AUTOSAR XML (schema 4-2-2)
package /ComponentTypes
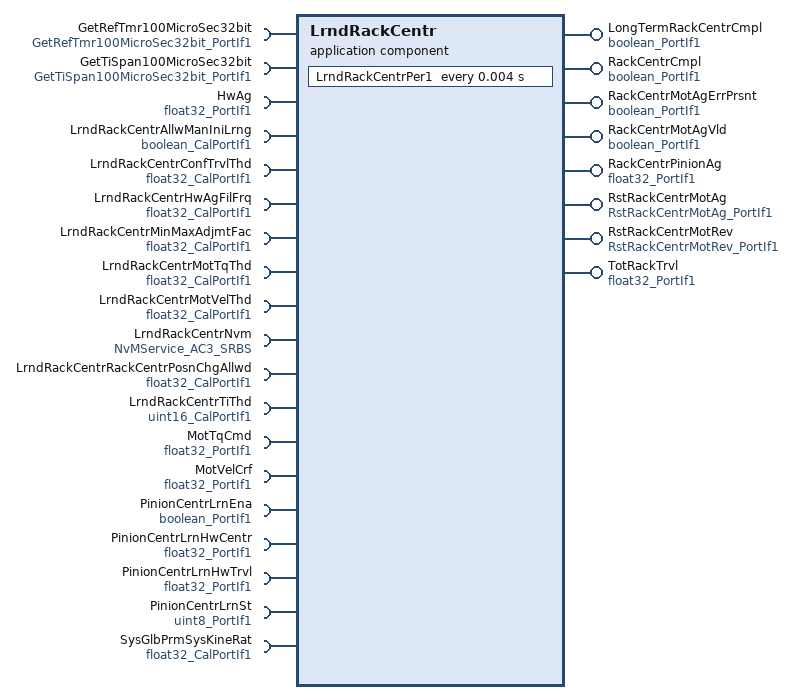
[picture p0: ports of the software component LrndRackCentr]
  application sw component type LrndRackCentr
    8 x provide port:
      LongTermRackCentrCmpl: nonqueued-sender-com-spec{data-element=Logl, init-value=0}, provided-interface=boolean_PortIf1
      RackCentrCmpl: nonqueued-sender-com-spec{data-element=Logl, init-value=0}, provided-interface=boolean_PortIf1
      RackCentrMotAgErrPrsnt: nonqueued-sender-com-spec{data-element=Logl, init-value=0}, provided-interface=boolean_PortIf1
      RackCentrMotAgVld: nonqueued-sender-com-spec{data-element=Logl, init-value=0}, provided-interface=boolean_PortIf1
      RackCentrPinionAg: nonqueued-sender-com-spec{data-element=Val, init-value=0}, provided-interface=float32_PortIf1
      RstRackCentrMotAg: server-com-spec{operation=Oper, queue-length=1}, provided-interface=RstRackCentrMotAg_PortIf1
      RstRackCentrMotRev: server-com-spec{operation=Oper, queue-length=1}, provided-interface=RstRackCentrMotRev_PortIf1
      TotRackTrvl: nonqueued-sender-com-spec{data-element=Val, init-value=0}, provided-interface=float32_PortIf1
    19 x require port:
      GetRefTmr100MicroSec32bit: client-com-spec=Oper, required-interface=GetRefTmr100MicroSec32bit_PortIf1
      GetTiSpan100MicroSec32bit: client-com-spec=Oper, required-interface=GetTiSpan100MicroSec32bit_PortIf1
      HwAg: nonqueued-receiver-com-spec{data-element=Val, filter=data-filter-type=ALWAYS, init-value=0}, required-interface=float32_PortIf1
      LrndRackCentrAllwManIniLrng: parameter-require-com-spec{init-value=1, parameter=Logl}, required-interface=boolean_CalPortIf1
      LrndRackCentrConfTrvlThd: parameter-require-com-spec{init-value=800, parameter=Val}, required-interface=float32_CalPortIf1
      LrndRackCentrHwAgFilFrq: parameter-require-com-spec{init-value=1, parameter=Val}, required-interface=float32_CalPortIf1
      LrndRackCentrMinMaxAdjmtFac: parameter-require-com-spec{init-value=0.25, parameter=Val}, required-interface=float32_CalPortIf1
      LrndRackCentrMotTqThd: parameter-require-com-spec{init-value=2.8, parameter=Val}, required-interface=float32_CalPortIf1
      LrndRackCentrMotVelThd: parameter-require-com-spec{init-value=25, parameter=Val}, required-interface=float32_CalPortIf1
      LrndRackCentrNvm: required-com-specs=[EraseBlock, GetErrorStatus, InvalidateNvBlock, ReadBlock, SetRamBlockStatus, WriteBlock], required-interface=NvMService_AC3_SRBS
      LrndRackCentrRackCentrPosnChgAllwd: parameter-require-com-spec{init-value=3, parameter=Val}, required-interface=float32_CalPortIf1
      LrndRackCentrTiThd: parameter-require-com-spec{init-value=200, parameter=Val}, required-interface=uint16_CalPortIf1
      MotTqCmd: nonqueued-receiver-com-spec{data-element=Val, filter=data-filter-type=ALWAYS, init-value=0}, required-interface=float32_PortIf1
      MotVelCrf: nonqueued-receiver-com-spec{data-element=Val, filter=data-filter-type=ALWAYS, init-value=0}, required-interface=float32_PortIf1
      PinionCentrLrnEna: nonqueued-receiver-com-spec{data-element=Logl, filter=data-filter-type=ALWAYS, init-value=0}, required-interface=boolean_PortIf1
      PinionCentrLrnHwCentr: nonqueued-receiver-com-spec{data-element=Val, filter=data-filter-type=ALWAYS, init-value=0}, required-interface=float32_PortIf1
      PinionCentrLrnHwTrvl: nonqueued-receiver-com-spec{data-element=Val, filter=data-filter-type=ALWAYS, init-value=0}, required-interface=float32_PortIf1
      PinionCentrLrnSt: nonqueued-receiver-com-spec{data-element=Val, filter=data-filter-type=ALWAYS, init-value=0}, required-interface=uint8_PortIf1
      SysGlbPrmSysKineRat: parameter-require-com-spec{init-value=22, parameter=Val}, required-interface=float32_CalPortIf1
    behavior LrndRackCentr_InternalBehavior: port-api-option{enable-take-address=false, error-handling=NO-TRANSFORMER-ERROR-HANDLING, indirect-api=false, port=LrndRackCentrNvm}
      ar-typed-per-instance-memorys:
        9 x data, all with sw-calibration-access=READ-ONLY:
          HwAgFil: type=FilLpRec1
          LrndRackCentr: type=LrndRackCentrNvmRec1
          ManLrndRackCentrNegEot: type=float32
          ManLrndRackCentrNegEotVld: type=boolean
          ManLrndRackCentrPosEot: type=float32
          ManLrndRackCentrPosEotVld: type=boolean
          RackCentrMaxTmr: type=uint32
          RackCentrMinTmr: type=uint32
          RackCentrPinionAgPrev: type=float32
      init event LrndRackCentr_InitEvent: start-on-event=LrndRackCentrInit1
      timing event TMT_LrndRackCentrPer1: start-on-event=LrndRackCentrPer1, period=0.004
      operation invoked event OIT_RstRackCentrMotAg_Oper_RstRackCentrMotAg_Oper: start-on-event=RstRackCentrMotAg_Oper, operation=RstRackCentrMotAg.Oper
      operation invoked event OIT_RstRackCentrMotRev_Oper_RstRackCentrMotRev_Oper: start-on-event=RstRackCentrMotRev_Oper, operation=RstRackCentrMotRev.Oper
      4 x runnable:
        LrndRackCentrInit1
          data-receive-point-by-arguments:
            access REC_HwAg_Val: accessed-variable=HwAg.Val
          data-send-points:
            5 x access:
              SEND_LongTermRackCentrCmpl_Logl: accessed-variable=LongTermRackCentrCmpl.Logl
              SEND_RackCentrCmpl_Logl: accessed-variable=RackCentrCmpl.Logl
              SEND_RackCentrMotAgErrPrsnt_Logl: accessed-variable=RackCentrMotAgErrPrsnt.Logl
              SEND_RackCentrMotAgVld_Logl: accessed-variable=RackCentrMotAgVld.Logl
              SEND_RackCentrPinionAg_Val: accessed-variable=RackCentrPinionAg.Val
          sync call SC_LrndRackCentrNvm_GetErrorStatus: operation=LrndRackCentrNvm.GetErrorStatus, timeout=0
        LrndRackCentrPer1
          data-receive-point-by-arguments:
            7 x access:
              REC_HwAg_Val: accessed-variable=HwAg.Val
              REC_MotTqCmd_Val: accessed-variable=MotTqCmd.Val
              REC_MotVelCrf_Val: accessed-variable=MotVelCrf.Val
              REC_PinionCentrLrnEna_Logl: accessed-variable=PinionCentrLrnEna.Logl
              REC_PinionCentrLrnHwCentr_Val: accessed-variable=PinionCentrLrnHwCentr.Val
              REC_PinionCentrLrnHwTrvl_Val: accessed-variable=PinionCentrLrnHwTrvl.Val
              REC_PinionCentrLrnSt_Val: accessed-variable=PinionCentrLrnSt.Val
          data-send-points:
            5 x access:
              SEND_LongTermRackCentrCmpl_Logl: accessed-variable=LongTermRackCentrCmpl.Logl
              SEND_RackCentrCmpl_Logl: accessed-variable=RackCentrCmpl.Logl
              SEND_RackCentrMotAgVld_Logl: accessed-variable=RackCentrMotAgVld.Logl
              SEND_RackCentrPinionAg_Val: accessed-variable=RackCentrPinionAg.Val
              SEND_TotRackTrvl_Val: accessed-variable=TotRackTrvl.Val
          sync call SC_GetRefTmr100MicroSec32bit_Oper: operation=GetRefTmr100MicroSec32bit.Oper, timeout=0
          sync call SC_GetTiSpan100MicroSec32bit_Oper: operation=GetTiSpan100MicroSec32bit.Oper, timeout=0
          sync call SC_LrndRackCentrNvm_SetRamBlockStatus: operation=LrndRackCentrNvm.SetRamBlockStatus, timeout=0
        RstRackCentrMotAg_Oper: can-be-invoked-concurrently=true
          data-send-points:
            access SEND_RackCentrMotAgVld_Logl: accessed-variable=RackCentrMotAgVld.Logl
          sync call SC_LrndRackCentrNvm_SetRamBlockStatus: operation=LrndRackCentrNvm.SetRamBlockStatus, timeout=0
        RstRackCentrMotRev_Oper: can-be-invoked-concurrently=true
          data-receive-point-by-arguments:
            access REC_HwAg_Val: accessed-variable=HwAg.Val
          data-send-points:
            access SEND_LongTermRackCentrCmpl_Logl: accessed-variable=LongTermRackCentrCmpl.Logl
            access SEND_RackCentrCmpl_Logl: accessed-variable=RackCentrCmpl.Logl
            access SEND_RackCentrPinionAg_Val: accessed-variable=RackCentrPinionAg.Val
          sync call SC_GetRefTmr100MicroSec32bit_Oper: operation=GetRefTmr100MicroSec32bit.Oper, timeout=0
          sync call SC_LrndRackCentrNvm_SetRamBlockStatus: operation=LrndRackCentrNvm.SetRamBlockStatus, timeout=0
      swc service dependency NvmLrndRackCentrNvm: assigned-datas=role-based-data-assignment={role=ramBlock, used-data-element=LrndRackCentr}, assigned-ports=role-based-port-assignment={port-prototype=LrndRackCentrNvm, role=NvMService_AC3_SRBS}
        service-needs:
          nv block needs NvmLrndRackCentrNvm: n-data-sets=0, ram-block-status-control=API, readonly=false, reliability=ERROR-DETECTION, resistant-to-changed-sw=true, restore-at-start=true, store-at-shutdown=true, write-only-once=false
  swc implementation LrndRackCentr_Implementation: behavior=LrndRackCentr_InternalBehavior
    code-descriptors:
      code Default: artifact-descriptors=autosar-engineering-object={short-label=Default, category=SWSRC}
